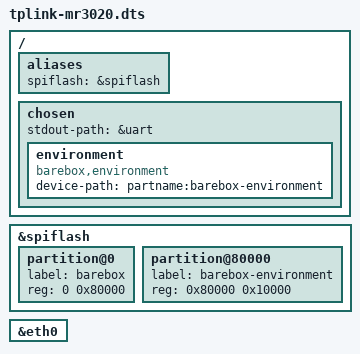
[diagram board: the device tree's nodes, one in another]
#include <mips/qca/ar9331_tl_mr3020.dts>
#include "ar9331.dtsi"

/ {
	aliases {
		spiflash = &spiflash;
	};

	chosen {
		stdout-path = &uart;

		environment {
			compatible = "barebox,environment";
			device-path = &spiflash, "partname:barebox-environment";
		};
	};
};

&spiflash {
	partition@0 {
		label = "barebox";
		reg = <0 0x80000>;
	};

	partition@80000 {
		label = "barebox-environment";
		reg = <0x80000 0x10000>;
	};
};

&eth0 {
	status = "okay";
};
